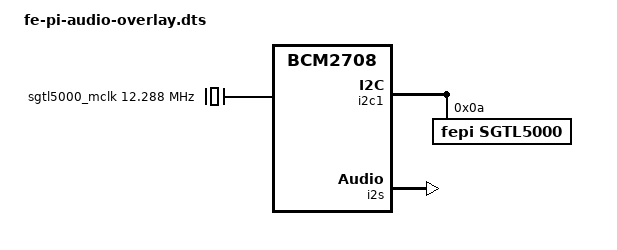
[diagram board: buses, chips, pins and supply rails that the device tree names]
// Definitions for Fe-Pi Audio
/dts-v1/;
/plugin/;

/ {
	compatible = "brcm,bcm2708";
	
	fragment@0 {
		target = <&clocks>;
		__overlay__ {
			sgtl5000_mclk: sgtl5000_mclk {
				compatible = "fixed-clock";
				#clock-cells = <0>;
				clock-frequency = <12288000>;
				clock-output-names = "sgtl5000-mclk";
			};
		};
	};
	
	fragment@1 {
		target = <&i2c1>;
		__overlay__ {
			#address-cells = <1>;
			#size-cells = <0>;
			status = "okay";

			sgtl5000@0a {
				#sound-dai-cells = <0>;
				compatible = "fepi,sgtl5000";
				reg = <0x0a>;
				clocks = <&sgtl5000_mclk>;
				micbias-resistor-k-ohms = <2>;
				micbias-voltage-m-volts = <3000>;
				VDDA-supply = <3300>;
				VDDIO-supply = <3300>;
				VDDD-supply = <1800>;
				status = "okay";
			};
		};
	};
	
	fragment@2 {
		target = <&i2s>;
		__overlay__ {
			status = "okay";
		};
	};

	fragment@3 {
		target = <&sound>;
		__overlay__ {
			compatible = "fe-pi,fe-pi-audio";
			i2s-controller = <&i2s>;
			status = "okay";
		};
	};	
};
